AUTOSAR XML (schema 4.0)
standard types defined: boolean, uint8, uint16
package /BaseDataTypes
  base type int16: category=SIGNED_INTEGER, lower-limit=-32768, upper-limit=32767
package /AppDataTypes
  impl type TemperatureType: category=VALUE, base-type=int16, sw-value-cont=20, lower-limit=-50, upper-limit=150
  impl type SpeedType: category=VALUE, base-type=uint16, sw-value-cont=0, lower-limit=0, upper-limit=500
  impl type SystemStatusType: category=VALUE, base-type=uint8, sw-value-cont=0, lower-limit=0, upper-limit=3
package /Interfaces
  sender receiver interface SensorDataInterface
    data TemperatureSensor: type=TemperatureType
    data SpeedSensor: type=SpeedType
  sender receiver interface ControlCommandInterface
    data MotorSpeedCommand: type=SpeedType
    data EnableCommand: type=boolean
  sender receiver interface SystemStatusInterface
    data SystemStatus: type=SystemStatusType
    data ErrorCode: type=uint16
  client server interface CalculationServiceInterface
    operation CalculateAverage
      client server argument Values: direction=IN, type=SpeedType
      client server argument Count: direction=IN, type=uint8
      client server argument Average: direction=OUT, type=SpeedType
    operation CheckThreshold
      client server argument Value: direction=IN, type=TemperatureType
      client server argument Threshold: direction=IN, type=TemperatureType
      client server argument IsExceeded: direction=OUT, type=boolean
package /SoftwareComponents
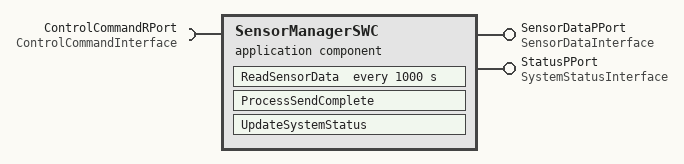
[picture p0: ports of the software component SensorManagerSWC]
  application software component type SensorManagerSWC
    provide port SensorDataPPort: provided-interface=SensorDataInterface
    provide port StatusPPort: provided-interface=SystemStatusInterface
    require port ControlCommandRPort: required-interface=ControlCommandInterface
    swc implementation SensorManagerImplementation: behavior=SensorManagerBehavior
    behavior SensorManagerBehavior
      timing event ReadSensorDataEvent: start-on-event=ReadSensorData, period=1000
      data send completed event DataSendCompletedEvent: start-on-event=ProcessSendComplete, data=SensorDataPPort
      runnable-entities:
        runnable ReadSensorData
        runnable ProcessSendComplete
        runnable UpdateSystemStatus
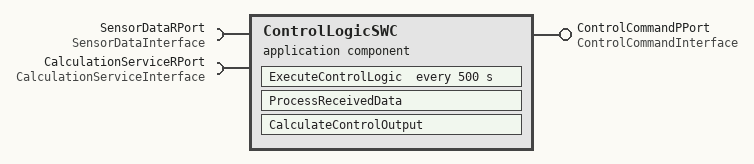
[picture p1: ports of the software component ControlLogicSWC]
  application software component type ControlLogicSWC
    require port SensorDataRPort: required-interface=SensorDataInterface
    provide port ControlCommandPPort: provided-interface=ControlCommandInterface
    require port CalculationServiceRPort: required-interface=CalculationServiceInterface
    swc implementation ControlLogicImplementation: behavior=ControlLogicBehavior
    behavior ControlLogicBehavior
      timing event ExecuteControlLogicEvent: start-on-event=ExecuteControlLogic, period=500
      data received event DataReceivedEvent: start-on-event=ProcessReceivedData, data=SensorDataRPort
      runnable-entities:
        runnable ExecuteControlLogic
        runnable ProcessReceivedData
        runnable CalculateControlOutput
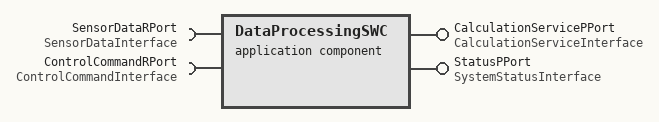
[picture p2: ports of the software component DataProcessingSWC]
  application software component type DataProcessingSWC
    require port SensorDataRPort: required-interface=SensorDataInterface
    require port ControlCommandRPort: required-interface=ControlCommandInterface
    provide port CalculationServicePPort: provided-interface=CalculationServiceInterface
    provide port StatusPPort: provided-interface=SystemStatusInterface
